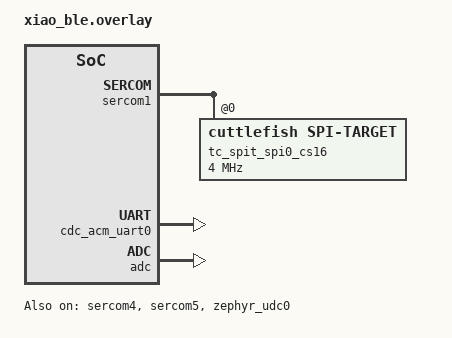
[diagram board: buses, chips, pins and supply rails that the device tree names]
/* Auto-generated by @typecad/framework-zephyr from typecad-hal.config.ts. */
/* Enables peripherals the program uses. West merges this over the board DT. */

&sercom4 {
    status = "okay";
};

&sercom1 {
    status = "okay";
};

&sercom1 {
    status = "okay";
};

&sercom5 {
    status = "okay";
};

&zephyr_udc0 {
    status = "okay";
    cdc_acm_uart0: cdc-acm-uart0 {
        compatible = "zephyr,cdc-acm-uart";
    };
};

&adc {
    status = "okay";
};

&sercom1 {
    cs-gpios = <&porta 16 GPIO_ACTIVE_LOW>;
    tc_spit_spi0_cs16: spidev@0 {
        compatible = "cuttlefish,spi-target";
        reg = <0>;
        spi-max-frequency = <4000000>;
    };
};
